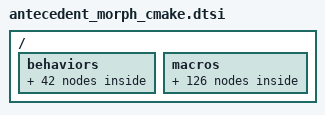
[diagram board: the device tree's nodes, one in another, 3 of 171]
// CMake schema version v0.8
// Automatically generated by Antecedent Morph Configurator

/ {
    behaviors {
        // Mod-Morphs
        // Base layer
        // NE
        amcmkneagm: amcmkneagm {
            compatible = "zmk,behavior-mod-morph";
            #binding-cells = <0>;
            bindings = <&amcmknea>, <&amcmkneg>;
            mods = <(MOD_LGUI)>;
        };
        amcmknecagm: amcmknecagm {
            compatible = "zmk,behavior-mod-morph";
            #binding-cells = <0>;
            bindings = <&amcmknec>, <&amcmkneagm>;
            mods = <(MOD_LALT|MOD_LGUI)>;
        };
        amcmknem: amcmknem {
            compatible = "zmk,behavior-mod-morph";
            #binding-cells = <0>;
            bindings = <&amcmkne>, <&amcmknecagm>;
            mods = <(MOD_LCTL|MOD_LALT|MOD_LGUI)>;
        };
        // E
        amcmkeagm: amcmkeagm {
            compatible = "zmk,behavior-mod-morph";
            #binding-cells = <0>;
            bindings = <&amcmkea>, <&amcmkeg>;
            mods = <(MOD_LGUI)>;
        };
        amcmkecagm: amcmkecagm {
            compatible = "zmk,behavior-mod-morph";
            #binding-cells = <0>;
            bindings = <&amcmkec>, <&amcmkeagm>;
            mods = <(MOD_LALT|MOD_LGUI)>;
        };
        amcmkem: amcmkem {
            compatible = "zmk,behavior-mod-morph";
            #binding-cells = <0>;
            bindings = <&amcmke>, <&amcmkecagm>;
            mods = <(MOD_LCTL|MOD_LALT|MOD_LGUI)>;
        };
        // SE
        amcmkseagm: amcmkseagm {
            compatible = "zmk,behavior-mod-morph";
            #binding-cells = <0>;
            bindings = <&amcmksea>, <&amcmkseg>;
            mods = <(MOD_LGUI)>;
        };
        amcmksecagm: amcmksecagm {
            compatible = "zmk,behavior-mod-morph";
            #binding-cells = <0>;
            bindings = <&amcmksec>, <&amcmkseagm>;
            mods = <(MOD_LALT|MOD_LGUI)>;
        };
        amcmksem: amcmksem {
            compatible = "zmk,behavior-mod-morph";
            #binding-cells = <0>;
            bindings = <&amcmkse>, <&amcmksecagm>;
            mods = <(MOD_LCTL|MOD_LALT|MOD_LGUI)>;
        };
        // NW
        amcmknwagm: amcmknwagm {
            compatible = "zmk,behavior-mod-morph";
            #binding-cells = <0>;
            bindings = <&amcmknwa>, <&amcmknwg>;
            mods = <(MOD_RGUI)>;
        };
        amcmknwcagm: amcmknwcagm {
            compatible = "zmk,behavior-mod-morph";
            #binding-cells = <0>;
            bindings = <&amcmknwc>, <&amcmknwagm>;
            mods = <(MOD_RALT|MOD_RGUI)>;
        };
        amcmknwm: amcmknwm {
            compatible = "zmk,behavior-mod-morph";
            #binding-cells = <0>;
            bindings = <&amcmknw>, <&amcmknwcagm>;
            mods = <(MOD_RCTL|MOD_RALT|MOD_RGUI)>;
        };
        // W
        amcmkwagm: amcmkwagm {
            compatible = "zmk,behavior-mod-morph";
            #binding-cells = <0>;
            bindings = <&amcmkwa>, <&amcmkwg>;
            mods = <(MOD_RGUI)>;
        };
        amcmkwcagm: amcmkwcagm {
            compatible = "zmk,behavior-mod-morph";
            #binding-cells = <0>;
            bindings = <&amcmkwc>, <&amcmkwagm>;
            mods = <(MOD_RALT|MOD_RGUI)>;
        };
        amcmkwm: amcmkwm {
            compatible = "zmk,behavior-mod-morph";
            #binding-cells = <0>;
            bindings = <&amcmkw>, <&amcmkwcagm>;
            mods = <(MOD_RCTL|MOD_RALT|MOD_RGUI)>;
        };
        // SW
        amcmkswagm: amcmkswagm {
            compatible = "zmk,behavior-mod-morph";
            #binding-cells = <0>;
            bindings = <&amcmkswa>, <&amcmkswg>;
            mods = <(MOD_RGUI)>;
        };
        amcmkswcagm: amcmkswcagm {
            compatible = "zmk,behavior-mod-morph";
            #binding-cells = <0>;
            bindings = <&amcmkswc>, <&amcmkswagm>;
            mods = <(MOD_RALT|MOD_RGUI)>;
        };
        amcmkswm: amcmkswm {
            compatible = "zmk,behavior-mod-morph";
            #binding-cells = <0>;
            bindings = <&amcmksw>, <&amcmkswcagm>;
            mods = <(MOD_RCTL|MOD_RALT|MOD_RGUI)>;
        };
        // Antecedent Morphs
        amcmkne: am_cmk_ne {
            compatible = "zmk,behavior-antecedent-morph";
            label = "AM_CMK_NE";
            #binding-cells = <0>;
            defaults = <&none>;
            bindings = <&amcmk_addexecutable>, <&amcmk_break>, <&amcmk_cmake>, <&amcmk_findprogram>, <&amcmk_generateexporth>, <&amcmk_object>, <&amcmk_public>, <&amcmk_required>, <&amcmk_static>, <&amcmk_targetsources>, <&amcmk_while>, <&amcmk_m>, <&amcmk_bool1>, <&kp DQT>, <&kp LT>, <&amcmk_standard>, <&amcmk_m2>;
            antecedents = <A B C F G O P R S T W SQT FSLH RBRC DLLR UNDER LBKT>;
            max-delay-ms = <U_ANTMORPH_DELAY>;
        };
        amcmknec: am_cmk_ne_c {
            compatible = "zmk,behavior-antecedent-morph";
            label = "AM_CMK_NE_C";
            #binding-cells = <0>;
            defaults = <&none>;
            bindings = <&amcmk_shared>, <&amcmk_endwhile>, <&amcmk_m1>, <&amcmk_standardrequire>;
            antecedents = <S W DLLR UNDER>;
            max-delay-ms = <U_ANTMORPH_DELAY>;
        };
        amcmknea: am_cmk_ne_a {
            compatible = "zmk,behavior-antecedent-morph";
            label = "AM_CMK_NE_A";
            #binding-cells = <0>;
            defaults = <&none>;
            bindings = <&amcmk_standardextensi>;
            antecedents = <UNDER>;
            max-delay-ms = <U_ANTMORPH_DELAY>;
        };
        amcmkneg: am_cmk_ne_g {
            compatible = "zmk,behavior-antecedent-morph";
            label = "AM_CMK_NE_G";
            #binding-cells = <0>;
            defaults = <&none>;
            bindings = <&none>;
            antecedents = <0x070100>;
            max-delay-ms = <U_ANTMORPH_DELAY>;
        };
        amcmke: am_cmk_e {
            compatible = "zmk,behavior-antecedent-morph";
            label = "AM_CMK_E";
            #binding-cells = <0>;
            defaults = <&none>;
            bindings = <&amcmk_addlibrary>, <&amcmk_bool>, <&amcmk_configurefile>, <&amcmk_executeprocess>, <&amcmk_findpackage>, <&amcmk_getcmakepropert>, <&amcmk_install>, <&amcmk_languages>, <&amcmk_project>, <&amcmk_return>, <&amcmk_set>, <&amcmk_targetlinklibra>, <&amcmk_version>, <&amcmk_01>, <&amcmk_10>, <&amcmk_330>, <&amcmk_cmake1>, <&amcmk_if1>, <&kp RPAR>, <&kp LBRC>, <&amcmk_not>, <&amcmk_only>, <&amcmk_or>, <&amcmk_and>, <&amcmk_currentsourcedi>, <&amcmk_m3>, <&amcmk_m6>, <&amcmk_cmake_v08>;
            antecedents = <A B C E F G I L P R S T V N0 N1 N3 DOT FSLH RBRC DLLR EXCL AT PIPE AMPS UNDER LBKT RBKT SPACE>;
            max-delay-ms = <U_ANTMORPH_DELAY>;
        };
        amcmkec: am_cmk_e_c {
            compatible = "zmk,behavior-antecedent-morph";
            label = "AM_CMK_E_C";
            #binding-cells = <0>;
            defaults = <&none>;
            bindings = <&amcmk_addlinkoptions>, <&amcmk_command>, <&amcmk_findlibrary>, <&amcmk_targetlinkoptio>, <&amcmk_cmake2>, <&amcmk_currentbinarydi>, <&amcmk_m4>, <&amcmk_m7>;
            antecedents = <A C F T DLLR UNDER LBKT RBKT>;
            max-delay-ms = <U_ANTMORPH_DELAY>;
        };
        amcmkea: am_cmk_e_a {
            compatible = "zmk,behavior-antecedent-morph";
            label = "AM_CMK_E_A";
            #binding-cells = <0>;
            defaults = <&none>;
            bindings = <&amcmk_currentlistdir>, <&amcmk_m5>, <&amcmk_m8>;
            antecedents = <UNDER LBKT RBKT>;
            max-delay-ms = <U_ANTMORPH_DELAY>;
        };
        amcmkeg: am_cmk_e_g {
            compatible = "zmk,behavior-antecedent-morph";
            label = "AM_CMK_E_G";
            #binding-cells = <0>;
            defaults = <&none>;
            bindings = <&amcmk_currentlistfile>;
            antecedents = <UNDER>;
            max-delay-ms = <U_ANTMORPH_DELAY>;
        };
        amcmkse: am_cmk_se {
            compatible = "zmk,behavior-antecedent-morph";
            label = "AM_CMK_SE";
            #binding-cells = <0>;
            defaults = <&none>;
            bindings = <&amcmk_addtestname>, <&amcmk_cmakeminimumreq>, <&amcmk_enabletesting>, <&amcmk_foreach>, <&amcmk_getproperty>, <&amcmk_private>, <&amcmk_setproperty>, <&amcmk_targetlinkdirec>, <&amcmk_regularexpressi>;
            antecedents = <A C E F G P S T UNDER>;
            max-delay-ms = <U_ANTMORPH_DELAY>;
        };
        amcmksec: am_cmk_se_c {
            compatible = "zmk,behavior-antecedent-morph";
            label = "AM_CMK_SE_C";
            #binding-cells = <0>;
            defaults = <&none>;
            bindings = <&amcmk_cmakepolicy>, <&amcmk_endforeach>, <&amcmk_settestspropert>, <&amcmk_istoplevel>;
            antecedents = <C F S UNDER>;
            max-delay-ms = <U_ANTMORPH_DELAY>;
        };
        amcmksea: am_cmk_se_a {
            compatible = "zmk,behavior-antecedent-morph";
            label = "AM_CMK_SE_A";
            #binding-cells = <0>;
            defaults = <&none>;
            bindings = <&none>;
            antecedents = <0x070100>;
            max-delay-ms = <U_ANTMORPH_DELAY>;
        };
        amcmkseg: am_cmk_se_g {
            compatible = "zmk,behavior-antecedent-morph";
            label = "AM_CMK_SE_G";
            #binding-cells = <0>;
            defaults = <&none>;
            bindings = <&none>;
            antecedents = <0x070100>;
            max-delay-ms = <U_ANTMORPH_DELAY>;
        };
        amcmknw: am_cmk_nw {
            compatible = "zmk,behavior-antecedent-morph";
            label = "AM_CMK_NW";
            #binding-cells = <0>;
            defaults = <&none>;
            bindings = <&amcmk_addsubdirectory>, <&amcmk_block>, <&amcmk_cmakepath>, <&amcmk_elseif>, <&amcmk_file>, <&amcmk_getfilenamecomp>, <&amcmk_include>, <&amcmk_module>, <&amcmk_project1>, <&amcmk_string>, <&amcmk_targetincludedi>, <&amcmk_install1>;
            antecedents = <A B C E F G I M P S T UNDER>;
            max-delay-ms = <U_ANTMORPH_DELAY>;
        };
        amcmknwc: am_cmk_nw_c {
            compatible = "zmk,behavior-antecedent-morph";
            label = "AM_CMK_NW_C";
            #binding-cells = <0>;
            defaults = <&none>;
            bindings = <&amcmk_adddependencies>, <&amcmk_endblock>, <&amcmk_findfile>, <&amcmk_targetprecompil>;
            antecedents = <A B F T>;
            max-delay-ms = <U_ANTMORPH_DELAY>;
        };
        amcmknwa: am_cmk_nw_a {
            compatible = "zmk,behavior-antecedent-morph";
            label = "AM_CMK_NW_A";
            #binding-cells = <0>;
            defaults = <&none>;
            bindings = <&amcmk_findpath>;
            antecedents = <F>;
            max-delay-ms = <U_ANTMORPH_DELAY>;
        };
        amcmknwg: am_cmk_nw_g {
            compatible = "zmk,behavior-antecedent-morph";
            label = "AM_CMK_NW_G";
            #binding-cells = <0>;
            defaults = <&none>;
            bindings = <&none>;
            antecedents = <0x070100>;
            max-delay-ms = <U_ANTMORPH_DELAY>;
        };
        amcmkw: am_cmk_w {
            compatible = "zmk,behavior-antecedent-morph";
            label = "AM_CMK_W";
            #binding-cells = <0>;
            defaults = <&none>;
            bindings = <&amcmk_addcompiledefin>, <&amcmk_continue>, <&amcmk_else>, <&amcmk_gettargetproper>, <&amcmk_headers>, <&amcmk_if>, <&amcmk_list>, <&amcmk_matches>, <&amcmk_false>, <&amcmk_option>, <&amcmk_properties>, <&amcmk_settargetproper>, <&amcmk_targetcompilede>, <&amcmk_true>, <&amcmk_cmakecommand>, <&amcmk_std>;
            antecedents = <A C E G H I L M N O P S T Y DLLR UNDER>;
            max-delay-ms = <U_ANTMORPH_DELAY>;
        };
        amcmkwc: am_cmk_w_c {
            compatible = "zmk,behavior-antecedent-morph";
            label = "AM_CMK_W_C";
            #binding-cells = <0>;
            defaults = <&none>;
            bindings = <&amcmk_addcompileoptio>, <&amcmk_getdirectorypro>, <&amcmk_endif>, <&amcmk_optionenable>, <&amcmk_setdirectorypro>, <&amcmk_targetcompileop>;
            antecedents = <A G I O S T>;
            max-delay-ms = <U_ANTMORPH_DELAY>;
        };
        amcmkwa: am_cmk_w_a {
            compatible = "zmk,behavior-antecedent-morph";
            label = "AM_CMK_W_A";
            #binding-cells = <0>;
            defaults = <&none>;
            bindings = <&amcmk_ifnot>, <&amcmk_targetcompilefe>;
            antecedents = <I T>;
            max-delay-ms = <U_ANTMORPH_DELAY>;
        };
        amcmkwg: am_cmk_w_g {
            compatible = "zmk,behavior-antecedent-morph";
            label = "AM_CMK_W_G";
            #binding-cells = <0>;
            defaults = <&none>;
            bindings = <&none>;
            antecedents = <0x070100>;
            max-delay-ms = <U_ANTMORPH_DELAY>;
        };
        amcmksw: am_cmk_sw {
            compatible = "zmk,behavior-antecedent-morph";
            label = "AM_CMK_SW";
            #binding-cells = <0>;
            defaults = <&none>;
            bindings = <&amcmk_addcustomtarget>, <&amcmk_cmakelanguage>, <&amcmk_fixturesrequire>, <&amcmk_getsourcefilepr>, <&amcmk_interface>, <&amcmk_message>, <&amcmk_resourcegroups>;
            antecedents = <A C F G I M R>;
            max-delay-ms = <U_ANTMORPH_DELAY>;
        };
        amcmkswc: am_cmk_sw_c {
            compatible = "zmk,behavior-antecedent-morph";
            label = "AM_CMK_SW_C";
            #binding-cells = <0>;
            defaults = <&none>;
            bindings = <&amcmk_addcustomcomman>, <&amcmk_fixturessetup>, <&amcmk_gettestproperty>, <&amcmk_imported>, <&amcmk_resourcelock>, <&amcmk_setsourcefilesp>;
            antecedents = <A F G I R S>;
            max-delay-ms = <U_ANTMORPH_DELAY>;
        };
        amcmkswa: am_cmk_sw_a {
            compatible = "zmk,behavior-antecedent-morph";
            label = "AM_CMK_SW_A";
            #binding-cells = <0>;
            defaults = <&none>;
            bindings = <&amcmk_fixturescleanup>;
            antecedents = <F>;
            max-delay-ms = <U_ANTMORPH_DELAY>;
        };
        amcmkswg: am_cmk_sw_g {
            compatible = "zmk,behavior-antecedent-morph";
            label = "AM_CMK_SW_G";
            #binding-cells = <0>;
            defaults = <&none>;
            bindings = <&none>;
            antecedents = <0x070100>;
            max-delay-ms = <U_ANTMORPH_DELAY>;
        };
    };
    macros {
        // 'A'
        amcmk_addexecutable: amcmk_addexecutable {
            compatible = "zmk,behavior-macro";
            #binding-cells = <0>;
            wait-ms = <U_ANTMORPH_MACRO_WAIT>;
            tap-ms = <U_ANTMORPH_MACRO_TAP>;
            // (a)dd_executable(
            bindings = <&macro_tap &kp D &kp D &kp UNDER &kp E &kp X &kp E &kp C &kp U &kp T &kp A &kp B &kp L &kp E &kp LPAR>;
        };
        amcmk_addlibrary: amcmk_addlibrary {
            compatible = "zmk,behavior-macro";
            #binding-cells = <0>;
            wait-ms = <U_ANTMORPH_MACRO_WAIT>;
            tap-ms = <U_ANTMORPH_MACRO_TAP>;
            // (a)dd_library(
            bindings = <&macro_tap &kp D &kp D &kp UNDER &kp L &kp I &kp B &kp R &kp A &kp R &kp Y &kp LPAR>;
        };
        amcmk_addlinkoptions: amcmk_addlinkoptions {
            compatible = "zmk,behavior-macro";
            #binding-cells = <0>;
            wait-ms = <U_ANTMORPH_MACRO_WAIT>;
            tap-ms = <U_ANTMORPH_MACRO_TAP>;
            // (a)dd_link_options(
            bindings = <&macro_release &kp LCTRL>, <&macro_tap &kp D &kp D &kp UNDER &kp L &kp I &kp N &kp K &kp UNDER &kp O &kp P &kp T &kp I &kp O &kp N &kp S &kp LPAR>;
        };
        amcmk_addtestname: amcmk_addtestname {
            compatible = "zmk,behavior-macro";
            #binding-cells = <0>;
            wait-ms = <U_ANTMORPH_MACRO_WAIT>;
            tap-ms = <U_ANTMORPH_MACRO_TAP>;
            // (a)dd_test(NAME 
            bindings = <&macro_tap &kp D &kp D &kp UNDER &kp T &kp E &kp S &kp T &kp LPAR &kp LS(N) &kp LS(A) &kp LS(M) &kp LS(E) &kp SPACE>;
        };
        amcmk_addsubdirectory: amcmk_addsubdirectory {
            compatible = "zmk,behavior-macro";
            #binding-cells = <0>;
            wait-ms = <U_ANTMORPH_MACRO_WAIT>;
            tap-ms = <U_ANTMORPH_MACRO_TAP>;
            // (a)dd_subdirectory(
            bindings = <&macro_tap &kp D &kp D &kp UNDER &kp S &kp U &kp B &kp D &kp I &kp R &kp E &kp C &kp T &kp O &kp R &kp Y &kp LPAR>;
        };
        amcmk_adddependencies: amcmk_adddependencies {
            compatible = "zmk,behavior-macro";
            #binding-cells = <0>;
            wait-ms = <U_ANTMORPH_MACRO_WAIT>;
            tap-ms = <U_ANTMORPH_MACRO_TAP>;
            // (a)dd_dependencies(
            bindings = <&macro_release &kp RCTRL>, <&macro_tap &kp D &kp D &kp UNDER &kp D &kp E &kp P &kp E &kp N &kp D &kp E &kp N &kp C &kp I &kp E &kp S &kp LPAR>;
        };
        amcmk_addcompiledefin: amcmk_addcompiledefin {
            compatible = "zmk,behavior-macro";
            #binding-cells = <0>;
            wait-ms = <U_ANTMORPH_MACRO_WAIT>;
            tap-ms = <U_ANTMORPH_MACRO_TAP>;
            // (a)dd_compile_definitions(
            bindings = <&macro_tap &kp D &kp D &kp UNDER &kp C &kp O &kp M &kp P &kp I &kp L &kp E &kp UNDER &kp D &kp E &kp F &kp I &kp N &kp I &kp T &kp I &kp O &kp N &kp S &kp LPAR>;
        };
        amcmk_addcompileoptio: amcmk_addcompileoptio {
            compatible = "zmk,behavior-macro";
            #binding-cells = <0>;
            wait-ms = <U_ANTMORPH_MACRO_WAIT>;
            tap-ms = <U_ANTMORPH_MACRO_TAP>;
            // (a)dd_compile_options(
            bindings = <&macro_release &kp RCTRL>, <&macro_tap &kp D &kp D &kp UNDER &kp C &kp O &kp M &kp P &kp I &kp L &kp E &kp UNDER &kp O &kp P &kp T &kp I &kp O &kp N &kp S &kp LPAR>;
        };
        amcmk_addcustomtarget: amcmk_addcustomtarget {
            compatible = "zmk,behavior-macro";
            #binding-cells = <0>;
            wait-ms = <U_ANTMORPH_MACRO_WAIT>;
            tap-ms = <U_ANTMORPH_MACRO_TAP>;
            // (a)dd_custom_target(
            bindings = <&macro_tap &kp D &kp D &kp UNDER &kp C &kp U &kp S &kp T &kp O &kp M &kp UNDER &kp T &kp A &kp R &kp G &kp E &kp T &kp LPAR>;
        };
        amcmk_addcustomcomman: amcmk_addcustomcomman {
            compatible = "zmk,behavior-macro";
            #binding-cells = <0>;
            wait-ms = <U_ANTMORPH_MACRO_WAIT>;
            tap-ms = <U_ANTMORPH_MACRO_TAP>;
            // (a)dd_custom_command(
            bindings = <&macro_release &kp RCTRL>, <&macro_tap &kp D &kp D &kp UNDER &kp C &kp U &kp S &kp T &kp O &kp M &kp UNDER &kp C &kp O &kp M &kp M &kp A &kp N &kp D &kp LPAR>;
        };
        // 'B'
        amcmk_break: amcmk_break {
            compatible = "zmk,behavior-macro";
            #binding-cells = <0>;
            wait-ms = <U_ANTMORPH_MACRO_WAIT>;
            tap-ms = <U_ANTMORPH_MACRO_TAP>;
            // (b)reak()
            bindings = <&macro_tap &kp R &kp E &kp A &kp K &kp LPAR &kp RPAR>;
        };
        amcmk_bool: amcmk_bool {
            compatible = "zmk,behavior-macro";
            #binding-cells = <0>;
            wait-ms = <U_ANTMORPH_MACRO_WAIT>;
            tap-ms = <U_ANTMORPH_MACRO_TAP>;
            // [b]$<BOOL:
            bindings = <&macro_tap &kp BSPC &kp DLLR &kp LT &kp LS(B) &kp LS(O) &kp LS(O) &kp LS(L) &kp COLON>;
        };
        amcmk_block: amcmk_block {
            compatible = "zmk,behavior-macro";
            #binding-cells = <0>;
            wait-ms = <U_ANTMORPH_MACRO_WAIT>;
            tap-ms = <U_ANTMORPH_MACRO_TAP>;
            // (b)lock()
            bindings = <&macro_tap &kp L &kp O &kp C &kp K &kp LPAR &kp RPAR>;
        };
        amcmk_endblock: amcmk_endblock {
            compatible = "zmk,behavior-macro";
            #binding-cells = <0>;
            wait-ms = <U_ANTMORPH_MACRO_WAIT>;
            tap-ms = <U_ANTMORPH_MACRO_TAP>;
            // [b]endblock()
            bindings = <&macro_release &kp RCTRL>, <&macro_tap &kp BSPC &kp E &kp N &kp D &kp B &kp L &kp O &kp C &kp K &kp LPAR &kp RPAR>;
        };
        // 'C'
        amcmk_cmake: amcmk_cmake {
            compatible = "zmk,behavior-macro";
            #binding-cells = <0>;
            wait-ms = <U_ANTMORPH_MACRO_WAIT>;
            tap-ms = <U_ANTMORPH_MACRO_TAP>;
            // [c]CMAKE_
            bindings = <&macro_tap &kp BSPC &kp LS(C) &kp LS(M) &kp LS(A) &kp LS(K) &kp LS(E) &kp UNDER>;
        };
        amcmk_configurefile: amcmk_configurefile {
            compatible = "zmk,behavior-macro";
            #binding-cells = <0>;
            wait-ms = <U_ANTMORPH_MACRO_WAIT>;
            tap-ms = <U_ANTMORPH_MACRO_TAP>;
            // (c)onfigure_file(
            bindings = <&macro_tap &kp O &kp N &kp F &kp I &kp G &kp U &kp R &kp E &kp UNDER &kp F &kp I &kp L &kp E &kp LPAR>;
        };
        amcmk_command: amcmk_command {
            compatible = "zmk,behavior-macro";
            #binding-cells = <0>;
            wait-ms = <U_ANTMORPH_MACRO_WAIT>;
            tap-ms = <U_ANTMORPH_MACRO_TAP>;
            // [c]COMMAND
            bindings = <&macro_release &kp LCTRL>, <&macro_tap &kp BSPC &kp LS(C) &kp LS(O) &kp LS(M) &kp LS(M) &kp LS(A) &kp LS(N) &kp LS(D)>;
        };
        amcmk_cmakeminimumreq: amcmk_cmakeminimumreq {
            compatible = "zmk,behavior-macro";
            #binding-cells = <0>;
            wait-ms = <U_ANTMORPH_MACRO_WAIT>;
            tap-ms = <U_ANTMORPH_MACRO_TAP>;
            // (c)make_minimum_required(VERSION 
            bindings = <&macro_tap &kp M &kp A &kp K &kp E &kp UNDER &kp M &kp I &kp N &kp I &kp M &kp U &kp M &kp UNDER &kp R &kp E &kp Q &kp U &kp I &kp R &kp E &kp D &kp LPAR &kp LS(V) &kp LS(E) &kp LS(R) &kp LS(S) &kp LS(I) &kp LS(O) &kp LS(N) &kp SPACE>;
        };
        amcmk_cmakepolicy: amcmk_cmakepolicy {
            compatible = "zmk,behavior-macro";
            #binding-cells = <0>;
            wait-ms = <U_ANTMORPH_MACRO_WAIT>;
            tap-ms = <U_ANTMORPH_MACRO_TAP>;
            // (c)make_policy(
            bindings = <&macro_release &kp LCTRL>, <&macro_tap &kp M &kp A &kp K &kp E &kp UNDER &kp P &kp O &kp L &kp I &kp C &kp Y &kp LPAR>;
        };
        amcmk_cmakepath: amcmk_cmakepath {
            compatible = "zmk,behavior-macro";
            #binding-cells = <0>;
            wait-ms = <U_ANTMORPH_MACRO_WAIT>;
            tap-ms = <U_ANTMORPH_MACRO_TAP>;
            // (c)make_path(
            bindings = <&macro_tap &kp M &kp A &kp K &kp E &kp UNDER &kp P &kp A &kp T &kp H &kp LPAR>;
        };
        amcmk_continue: amcmk_continue {
            compatible = "zmk,behavior-macro";
            #binding-cells = <0>;
            wait-ms = <U_ANTMORPH_MACRO_WAIT>;
            tap-ms = <U_ANTMORPH_MACRO_TAP>;
            // (c)ontinue()
            bindings = <&macro_tap &kp O &kp N &kp T &kp I &kp N &kp U &kp E &kp LPAR &kp RPAR>;
        };
        amcmk_cmakelanguage: amcmk_cmakelanguage {
            compatible = "zmk,behavior-macro";
            #binding-cells = <0>;
            wait-ms = <U_ANTMORPH_MACRO_WAIT>;
            tap-ms = <U_ANTMORPH_MACRO_TAP>;
            // (c)make_language(
            bindings = <&macro_tap &kp M &kp A &kp K &kp E &kp UNDER &kp L &kp A &kp N &kp G &kp U &kp A &kp G &kp E &kp LPAR>;
        };
        // 'E'
        amcmk_executeprocess: amcmk_executeprocess {
            compatible = "zmk,behavior-macro";
            #binding-cells = <0>;
            wait-ms = <U_ANTMORPH_MACRO_WAIT>;
            tap-ms = <U_ANTMORPH_MACRO_TAP>;
            // (e)xecute_process(
            bindings = <&macro_tap &kp X &kp E &kp C &kp U &kp T &kp E &kp UNDER &kp P &kp R &kp O &kp C &kp E &kp S &kp S &kp LPAR>;
        };
        amcmk_enabletesting: amcmk_enabletesting {
            compatible = "zmk,behavior-macro";
            #binding-cells = <0>;
            wait-ms = <U_ANTMORPH_MACRO_WAIT>;
            tap-ms = <U_ANTMORPH_MACRO_TAP>;
            // (e)nable_testing()
            bindings = <&macro_tap &kp N &kp A &kp B &kp L &kp E &kp UNDER &kp T &kp E &kp S &kp T &kp I &kp N &kp G &kp LPAR &kp RPAR>;
        };
        amcmk_elseif: amcmk_elseif {
            compatible = "zmk,behavior-macro";
            #binding-cells = <0>;
            wait-ms = <U_ANTMORPH_MACRO_WAIT>;
            tap-ms = <U_ANTMORPH_MACRO_TAP>;
            // (e)lseif(
            bindings = <&macro_tap &kp L &kp S &kp E &kp I &kp F &kp LPAR>;
        };
        amcmk_else: amcmk_else {
            compatible = "zmk,behavior-macro";
            #binding-cells = <0>;
            wait-ms = <U_ANTMORPH_MACRO_WAIT>;
            tap-ms = <U_ANTMORPH_MACRO_TAP>;
            // (e)lse()
            bindings = <&macro_tap &kp L &kp S &kp E &kp LPAR &kp RPAR>;
        };
        // 'F'
        amcmk_findprogram: amcmk_findprogram {
            compatible = "zmk,behavior-macro";
            #binding-cells = <0>;
            wait-ms = <U_ANTMORPH_MACRO_WAIT>;
            tap-ms = <U_ANTMORPH_MACRO_TAP>;
            // (f)ind_program(
            bindings = <&macro_tap &kp I &kp N &kp D &kp UNDER &kp P &kp R &kp O &kp G &kp R &kp A &kp M &kp LPAR>;
        };
        amcmk_findpackage: amcmk_findpackage {
            compatible = "zmk,behavior-macro";
            #binding-cells = <0>;
            wait-ms = <U_ANTMORPH_MACRO_WAIT>;
            tap-ms = <U_ANTMORPH_MACRO_TAP>;
            // (f)ind_package(
            bindings = <&macro_tap &kp I &kp N &kp D &kp UNDER &kp P &kp A &kp C &kp K &kp A &kp G &kp E &kp LPAR>;
        };
        amcmk_findlibrary: amcmk_findlibrary {
            compatible = "zmk,behavior-macro";
            #binding-cells = <0>;
            wait-ms = <U_ANTMORPH_MACRO_WAIT>;
            tap-ms = <U_ANTMORPH_MACRO_TAP>;
            // (f)ind_library(
            bindings = <&macro_release &kp LCTRL>, <&macro_tap &kp I &kp N &kp D &kp UNDER &kp L &kp I &kp B &kp R &kp A &kp R &kp Y &kp LPAR>;
        };
        amcmk_foreach: amcmk_foreach {
            compatible = "zmk,behavior-macro";
            #binding-cells = <0>;
            wait-ms = <U_ANTMORPH_MACRO_WAIT>;
            tap-ms = <U_ANTMORPH_MACRO_TAP>;
            // (f)oreach(
            bindings = <&macro_tap &kp O &kp R &kp E &kp A &kp C &kp H &kp LPAR>;
        };
        amcmk_endforeach: amcmk_endforeach {
            compatible = "zmk,behavior-macro";
            #binding-cells = <0>;
            wait-ms = <U_ANTMORPH_MACRO_WAIT>;
            tap-ms = <U_ANTMORPH_MACRO_TAP>;
            // [f]endforeach()
            bindings = <&macro_release &kp LCTRL>, <&macro_tap &kp BSPC &kp E &kp N &kp D &kp F &kp O &kp R &kp E &kp A &kp C &kp H &kp LPAR &kp RPAR>;
        };
        amcmk_file: amcmk_file {
            compatible = "zmk,behavior-macro";
            #binding-cells = <0>;
            wait-ms = <U_ANTMORPH_MACRO_WAIT>;
            tap-ms = <U_ANTMORPH_MACRO_TAP>;
            // (f)ile(
            bindings = <&macro_tap &kp I &kp L &kp E &kp LPAR>;
        };
        amcmk_findfile: amcmk_findfile {
            compatible = "zmk,behavior-macro";
            #binding-cells = <0>;
            wait-ms = <U_ANTMORPH_MACRO_WAIT>;
            tap-ms = <U_ANTMORPH_MACRO_TAP>;
            // (f)ind_file(
            bindings = <&macro_release &kp RCTRL>, <&macro_tap &kp I &kp N &kp D &kp UNDER &kp F &kp I &kp L &kp E &kp LPAR>;
        };
        amcmk_findpath: amcmk_findpath {
            compatible = "zmk,behavior-macro";
            #binding-cells = <0>;
            wait-ms = <U_ANTMORPH_MACRO_WAIT>;
            tap-ms = <U_ANTMORPH_MACRO_TAP>;
            // (f)ind_path(
            bindings = <&macro_release &kp RALT>, <&macro_tap &kp RALT>, <&macro_tap &kp I &kp N &kp D &kp UNDER &kp P &kp A &kp T &kp H &kp LPAR>;
        };
        amcmk_fixturesrequire: amcmk_fixturesrequire {
            compatible = "zmk,behavior-macro";
            #binding-cells = <0>;
            wait-ms = <U_ANTMORPH_MACRO_WAIT>;
            tap-ms = <U_ANTMORPH_MACRO_TAP>;
            // [f]FIXTURES_REQUIRED
            bindings = <&macro_tap &kp BSPC &kp LS(F) &kp LS(I) &kp LS(X) &kp LS(T) &kp LS(U) &kp LS(R) &kp LS(E) &kp LS(S) &kp UNDER &kp LS(R) &kp LS(E) &kp LS(Q) &kp LS(U) &kp LS(I) &kp LS(R) &kp LS(E) &kp LS(D)>;
        };
        amcmk_fixturessetup: amcmk_fixturessetup {
            compatible = "zmk,behavior-macro";
            #binding-cells = <0>;
            wait-ms = <U_ANTMORPH_MACRO_WAIT>;
            tap-ms = <U_ANTMORPH_MACRO_TAP>;
            // [f]FIXTURES_SETUP
            bindings = <&macro_release &kp RCTRL>, <&macro_tap &kp BSPC &kp LS(F) &kp LS(I) &kp LS(X) &kp LS(T) &kp LS(U) &kp LS(R) &kp LS(E) &kp LS(S) &kp UNDER &kp LS(S) &kp LS(E) &kp LS(T) &kp LS(U) &kp LS(P)>;
        };
        amcmk_fixturescleanup: amcmk_fixturescleanup {
            compatible = "zmk,behavior-macro";
            #binding-cells = <0>;
            wait-ms = <U_ANTMORPH_MACRO_WAIT>;
            tap-ms = <U_ANTMORPH_MACRO_TAP>;
            // [f]FIXTURES_CLEANUP
            bindings = <&macro_release &kp RALT>, <&macro_tap &kp RALT>, <&macro_tap &kp BSPC &kp LS(F) &kp LS(I) &kp LS(X) &kp LS(T) &kp LS(U) &kp LS(R) &kp LS(E) &kp LS(S) &kp UNDER &kp LS(C) &kp LS(L) &kp LS(E) &kp LS(A) &kp LS(N) &kp LS(U) &kp LS(P)>;
        };
        // 'G'
        amcmk_generateexporth: amcmk_generateexporth {
            compatible = "zmk,behavior-macro";
            #binding-cells = <0>;
            wait-ms = <U_ANTMORPH_MACRO_WAIT>;
            tap-ms = <U_ANTMORPH_MACRO_TAP>;
            // (g)enerate_export_header(
            bindings = <&macro_tap &kp E &kp N &kp E &kp R &kp A &kp T &kp E &kp UNDER &kp E &kp X &kp P &kp O &kp R &kp T &kp UNDER &kp H &kp E &kp A &kp D &kp E &kp R &kp LPAR>;
        };
        amcmk_getcmakepropert: amcmk_getcmakepropert {
            compatible = "zmk,behavior-macro";
            #binding-cells = <0>;
            wait-ms = <U_ANTMORPH_MACRO_WAIT>;
            tap-ms = <U_ANTMORPH_MACRO_TAP>;
            // (g)et_cmake_property(
            bindings = <&macro_tap &kp E &kp T &kp UNDER &kp C &kp M &kp A &kp K &kp E &kp UNDER &kp P &kp R &kp O &kp P &kp E &kp R &kp T &kp Y &kp LPAR>;
        };
        amcmk_getproperty: amcmk_getproperty {
            compatible = "zmk,behavior-macro";
            #binding-cells = <0>;
            wait-ms = <U_ANTMORPH_MACRO_WAIT>;
            tap-ms = <U_ANTMORPH_MACRO_TAP>;
            // (g)et_property(
            bindings = <&macro_tap &kp E &kp T &kp UNDER &kp P &kp R &kp O &kp P &kp E &kp R &kp T &kp Y &kp LPAR>;
        };
        amcmk_getfilenamecomp: amcmk_getfilenamecomp {
            compatible = "zmk,behavior-macro";
            #binding-cells = <0>;
            wait-ms = <U_ANTMORPH_MACRO_WAIT>;
            tap-ms = <U_ANTMORPH_MACRO_TAP>;
            // (g)et_filename_component(
            bindings = <&macro_tap &kp E &kp T &kp UNDER &kp F &kp I &kp L &kp E &kp N &kp A &kp M &kp E &kp UNDER &kp C &kp O &kp M &kp P &kp O &kp N &kp E &kp N &kp T &kp LPAR>;
        };
        amcmk_gettargetproper: amcmk_gettargetproper {
            compatible = "zmk,behavior-macro";
            #binding-cells = <0>;
            wait-ms = <U_ANTMORPH_MACRO_WAIT>;
            tap-ms = <U_ANTMORPH_MACRO_TAP>;
            // (g)et_target_property(
            bindings = <&macro_tap &kp E &kp T &kp UNDER &kp T &kp A &kp R &kp G &kp E &kp T &kp UNDER &kp P &kp R &kp O &kp P &kp E &kp R &kp T &kp Y &kp LPAR>;
        };
        amcmk_getdirectorypro: amcmk_getdirectorypro {
            compatible = "zmk,behavior-macro";
            #binding-cells = <0>;
            wait-ms = <U_ANTMORPH_MACRO_WAIT>;
            tap-ms = <U_ANTMORPH_MACRO_TAP>;
            // (g)et_directory_property(
            bindings = <&macro_release &kp RCTRL>, <&macro_tap &kp E &kp T &kp UNDER &kp D &kp I &kp R &kp E &kp C &kp T &kp O &kp R &kp Y &kp UNDER &kp P &kp R &kp O &kp P &kp E &kp R &kp T &kp Y &kp LPAR>;
        };
        amcmk_getsourcefilepr: amcmk_getsourcefilepr {
            compatible = "zmk,behavior-macro";
            #binding-cells = <0>;
            wait-ms = <U_ANTMORPH_MACRO_WAIT>;
            tap-ms = <U_ANTMORPH_MACRO_TAP>;
            // (g)et_source_file_property(
            bindings = <&macro_tap &kp E &kp T &kp UNDER &kp S &kp O &kp U &kp R &kp C &kp E &kp UNDER &kp F &kp I &kp L &kp E &kp UNDER &kp P &kp R &kp O &kp P &kp E &kp R &kp T &kp Y &kp LPAR>;
        };
        amcmk_gettestproperty: amcmk_gettestproperty {
            compatible = "zmk,behavior-macro";
            #binding-cells = <0>;
            wait-ms = <U_ANTMORPH_MACRO_WAIT>;
            tap-ms = <U_ANTMORPH_MACRO_TAP>;
            // (g)et_test_property(
            bindings = <&macro_release &kp RCTRL>, <&macro_tap &kp E &kp T &kp UNDER &kp T &kp E &kp S &kp T &kp UNDER &kp P &kp R &kp O &kp P &kp E &kp R &kp T &kp Y &kp LPAR>;
        };
        // 'H'
        amcmk_headers: amcmk_headers {
            compatible = "zmk,behavior-macro";
            #binding-cells = <0>;
            wait-ms = <U_ANTMORPH_MACRO_WAIT>;
            tap-ms = <U_ANTMORPH_MACRO_TAP>;
            // [h]HEADERS
            bindings = <&macro_tap &kp BSPC &kp LS(H) &kp LS(E) &kp LS(A) &kp LS(D) &kp LS(E) &kp LS(R) &kp LS(S)>;
        };
        // 'I'
        amcmk_install: amcmk_install {
            compatible = "zmk,behavior-macro";
            #binding-cells = <0>;
            wait-ms = <U_ANTMORPH_MACRO_WAIT>;
            tap-ms = <U_ANTMORPH_MACRO_TAP>;
            // (i)nstall(
            bindings = <&macro_tap &kp N &kp S &kp T &kp A &kp L &kp L &kp LPAR>;
        };
        amcmk_include: amcmk_include {
            compatible = "zmk,behavior-macro";
            #binding-cells = <0>;
            wait-ms = <U_ANTMORPH_MACRO_WAIT>;
            tap-ms = <U_ANTMORPH_MACRO_TAP>;
            // (i)nclude(
            bindings = <&macro_tap &kp N &kp C &kp L &kp U &kp D &kp E &kp LPAR>;
        };
        amcmk_if: amcmk_if {
            compatible = "zmk,behavior-macro";
            #binding-cells = <0>;
            wait-ms = <U_ANTMORPH_MACRO_WAIT>;
            tap-ms = <U_ANTMORPH_MACRO_TAP>;
            // (i)f(
            bindings = <&macro_tap &kp F &kp LPAR>;
        };
        amcmk_endif: amcmk_endif {
            compatible = "zmk,behavior-macro";
            #binding-cells = <0>;
            wait-ms = <U_ANTMORPH_MACRO_WAIT>;
            tap-ms = <U_ANTMORPH_MACRO_TAP>;
            // [i]endif()
            bindings = <&macro_release &kp RCTRL>, <&macro_tap &kp BSPC &kp E &kp N &kp D &kp I &kp F &kp LPAR &kp RPAR>;
        };
        amcmk_ifnot: amcmk_ifnot {
            compatible = "zmk,behavior-macro";
            #binding-cells = <0>;
            wait-ms = <U_ANTMORPH_MACRO_WAIT>;
            tap-ms = <U_ANTMORPH_MACRO_TAP>;
            // (i)f(NOT 
            bindings = <&macro_release &kp RALT>, <&macro_tap &kp RALT>, <&macro_tap &kp F &kp LPAR &kp LS(N) &kp LS(O) &kp LS(T) &kp SPACE>;
        };
        amcmk_interface: amcmk_interface {
            compatible = "zmk,behavior-macro";
            #binding-cells = <0>;
            wait-ms = <U_ANTMORPH_MACRO_WAIT>;
            tap-ms = <U_ANTMORPH_MACRO_TAP>;
            // [i]INTERFACE
            bindings = <&macro_tap &kp BSPC &kp LS(I) &kp LS(N) &kp LS(T) &kp LS(E) &kp LS(R) &kp LS(F) &kp LS(A) &kp LS(C) &kp LS(E)>;
        };
        amcmk_imported: amcmk_imported {
            compatible = "zmk,behavior-macro";
            #binding-cells = <0>;
            wait-ms = <U_ANTMORPH_MACRO_WAIT>;
            tap-ms = <U_ANTMORPH_MACRO_TAP>;
            // [i]IMPORTED
            bindings = <&macro_release &kp RCTRL>, <&macro_tap &kp BSPC &kp LS(I) &kp LS(M) &kp LS(P) &kp LS(O) &kp LS(R) &kp LS(T) &kp LS(E) &kp LS(D)>;
        };
        // 'L'
        amcmk_languages: amcmk_languages {
            compatible = "zmk,behavior-macro";
            #binding-cells = <0>;
            wait-ms = <U_ANTMORPH_MACRO_WAIT>;
            tap-ms = <U_ANTMORPH_MACRO_TAP>;
            // [l]LANGUAGES
            bindings = <&macro_tap &kp BSPC &kp LS(L) &kp LS(A) &kp LS(N) &kp LS(G) &kp LS(U) &kp LS(A) &kp LS(G) &kp LS(E) &kp LS(S)>;
        };
        amcmk_list: amcmk_list {
            compatible = "zmk,behavior-macro";
            #binding-cells = <0>;
            wait-ms = <U_ANTMORPH_MACRO_WAIT>;
            tap-ms = <U_ANTMORPH_MACRO_TAP>;
            // (l)ist(
            bindings = <&macro_tap &kp I &kp S &kp T &kp LPAR>;
        };
        // 'M'
        amcmk_module: amcmk_module {
            compatible = "zmk,behavior-macro";
            #binding-cells = <0>;
            wait-ms = <U_ANTMORPH_MACRO_WAIT>;
            tap-ms = <U_ANTMORPH_MACRO_TAP>;
            // [m]MODULE
            bindings = <&macro_tap &kp BSPC &kp LS(M) &kp LS(O) &kp LS(D) &kp LS(U) &kp LS(L) &kp LS(E)>;
        };
        amcmk_matches: amcmk_matches {
            compatible = "zmk,behavior-macro";
            #binding-cells = <0>;
            wait-ms = <U_ANTMORPH_MACRO_WAIT>;
            tap-ms = <U_ANTMORPH_MACRO_TAP>;
            // [m]MATCHES
            bindings = <&macro_tap &kp BSPC &kp LS(M) &kp LS(A) &kp LS(T) &kp LS(C) &kp LS(H) &kp LS(E) &kp LS(S)>;
        };
        amcmk_message: amcmk_message {
            compatible = "zmk,behavior-macro";
            #binding-cells = <0>;
            wait-ms = <U_ANTMORPH_MACRO_WAIT>;
            tap-ms = <U_ANTMORPH_MACRO_TAP>;
            // (m)essage(
            bindings = <&macro_tap &kp E &kp S &kp S &kp A &kp G &kp E &kp LPAR>;
        };
        // 'N'
        amcmk_false: amcmk_false {
            compatible = "zmk,behavior-macro";
            #binding-cells = <0>;
            wait-ms = <U_ANTMORPH_MACRO_WAIT>;
            tap-ms = <U_ANTMORPH_MACRO_TAP>;
            // [n]FALSE
            bindings = <&macro_tap &kp BSPC &kp LS(F) &kp LS(A) &kp LS(L) &kp LS(S) &kp LS(E)>;
        };
        // 'O'
        amcmk_object: amcmk_object {
            compatible = "zmk,behavior-macro";
            #binding-cells = <0>;
            wait-ms = <U_ANTMORPH_MACRO_WAIT>;
            tap-ms = <U_ANTMORPH_MACRO_TAP>;
            // [o]OBJECT
            bindings = <&macro_tap &kp BSPC &kp LS(O) &kp LS(B) &kp LS(J) &kp LS(E) &kp LS(C) &kp LS(T)>;
        };
        amcmk_option: amcmk_option {
            compatible = "zmk,behavior-macro";
            #binding-cells = <0>;
            wait-ms = <U_ANTMORPH_MACRO_WAIT>;
            tap-ms = <U_ANTMORPH_MACRO_TAP>;
            // (o)ption(
            bindings = <&macro_tap &kp P &kp T &kp I &kp O &kp N &kp LPAR>;
        };
        amcmk_optionenable: amcmk_optionenable {
            compatible = "zmk,behavior-macro";
            #binding-cells = <0>;
            wait-ms = <U_ANTMORPH_MACRO_WAIT>;
            tap-ms = <U_ANTMORPH_MACRO_TAP>;
            // (o)ption(ENABLE_
            bindings = <&macro_release &kp RCTRL>, <&macro_tap &kp P &kp T &kp I &kp O &kp N &kp LPAR &kp LS(E) &kp LS(N) &kp LS(A) &kp LS(B) &kp LS(L) &kp LS(E) &kp UNDER>;
        };
        // 'P'
        amcmk_public: amcmk_public {
            compatible = "zmk,behavior-macro";
            #binding-cells = <0>;
            wait-ms = <U_ANTMORPH_MACRO_WAIT>;
            tap-ms = <U_ANTMORPH_MACRO_TAP>;
            // [p]PUBLIC
            bindings = <&macro_tap &kp BSPC &kp LS(P) &kp LS(U) &kp LS(B) &kp LS(L) &kp LS(I) &kp LS(C)>;
        };
        amcmk_project: amcmk_project {
            compatible = "zmk,behavior-macro";
            #binding-cells = <0>;
            wait-ms = <U_ANTMORPH_MACRO_WAIT>;
            tap-ms = <U_ANTMORPH_MACRO_TAP>;
            // (p)roject(
            bindings = <&macro_tap &kp R &kp O &kp J &kp E &kp C &kp T &kp LPAR>;
        };
        amcmk_private: amcmk_private {
            compatible = "zmk,behavior-macro";
            #binding-cells = <0>;
            wait-ms = <U_ANTMORPH_MACRO_WAIT>;
            tap-ms = <U_ANTMORPH_MACRO_TAP>;
            // [p]PRIVATE
            bindings = <&macro_tap &kp BSPC &kp LS(P) &kp LS(R) &kp LS(I) &kp LS(V) &kp LS(A) &kp LS(T) &kp LS(E)>;
        };
        amcmk_project1: amcmk_project1 {
            compatible = "zmk,behavior-macro";
            #binding-cells = <0>;
            wait-ms = <U_ANTMORPH_MACRO_WAIT>;
            tap-ms = <U_ANTMORPH_MACRO_TAP>;
            // [p]PROJECT_
            bindings = <&macro_tap &kp BSPC &kp LS(P) &kp LS(R) &kp LS(O) &kp LS(J) &kp LS(E) &kp LS(C) &kp LS(T) &kp UNDER>;
        };
        amcmk_properties: amcmk_properties {
            compatible = "zmk,behavior-macro";
            #binding-cells = <0>;
            wait-ms = <U_ANTMORPH_MACRO_WAIT>;
            tap-ms = <U_ANTMORPH_MACRO_TAP>;
            // [p]PROPERTIES
            bindings = <&macro_tap &kp BSPC &kp LS(P) &kp LS(R) &kp LS(O) &kp LS(P) &kp LS(E) &kp LS(R) &kp LS(T) &kp LS(I) &kp LS(E) &kp LS(S)>;
        };
        // 'R'
        amcmk_required: amcmk_required {
            compatible = "zmk,behavior-macro";
            #binding-cells = <0>;
            wait-ms = <U_ANTMORPH_MACRO_WAIT>;
            tap-ms = <U_ANTMORPH_MACRO_TAP>;
            // [r]REQUIRED
            bindings = <&macro_tap &kp BSPC &kp LS(R) &kp LS(E) &kp LS(Q) &kp LS(U) &kp LS(I) &kp LS(R) &kp LS(E) &kp LS(D)>;
        };
        amcmk_return: amcmk_return {
            compatible = "zmk,behavior-macro";
            #binding-cells = <0>;
            wait-ms = <U_ANTMORPH_MACRO_WAIT>;
            tap-ms = <U_ANTMORPH_MACRO_TAP>;
            // (r)eturn(
            bindings = <&macro_tap &kp E &kp T &kp U &kp R &kp N &kp LPAR>;
        };
        amcmk_resourcegroups: amcmk_resourcegroups {
            compatible = "zmk,behavior-macro";
            #binding-cells = <0>;
            wait-ms = <U_ANTMORPH_MACRO_WAIT>;
            tap-ms = <U_ANTMORPH_MACRO_TAP>;
            // [r]RESOURCE_GROUPS
            bindings = <&macro_tap &kp BSPC &kp LS(R) &kp LS(E) &kp LS(S) &kp LS(O) &kp LS(U) &kp LS(R) &kp LS(C) &kp LS(E) &kp UNDER &kp LS(G) &kp LS(R) &kp LS(O) &kp LS(U) &kp LS(P) &kp LS(S)>;
        };
        amcmk_resourcelock: amcmk_resourcelock {
            compatible = "zmk,behavior-macro";
            #binding-cells = <0>;
            wait-ms = <U_ANTMORPH_MACRO_WAIT>;
            tap-ms = <U_ANTMORPH_MACRO_TAP>;
            // [r]RESOURCE_LOCK
            bindings = <&macro_release &kp RCTRL>, <&macro_tap &kp BSPC &kp LS(R) &kp LS(E) &kp LS(S) &kp LS(O) &kp LS(U) &kp LS(R) &kp LS(C) &kp LS(E) &kp UNDER &kp LS(L) &kp LS(O) &kp LS(C) &kp LS(K)>;
        };
        // 'S'
        amcmk_static: amcmk_static {
            compatible = "zmk,behavior-macro";
            #binding-cells = <0>;
            wait-ms = <U_ANTMORPH_MACRO_WAIT>;
            tap-ms = <U_ANTMORPH_MACRO_TAP>;
            // [s]STATIC
            bindings = <&macro_tap &kp BSPC &kp LS(S) &kp LS(T) &kp LS(A) &kp LS(T) &kp LS(I) &kp LS(C)>;
        };
        amcmk_shared: amcmk_shared {
            compatible = "zmk,behavior-macro";
            #binding-cells = <0>;
            wait-ms = <U_ANTMORPH_MACRO_WAIT>;
            tap-ms = <U_ANTMORPH_MACRO_TAP>;
            // [s]SHARED
            bindings = <&macro_release &kp LCTRL>, <&macro_tap &kp BSPC &kp LS(S) &kp LS(H) &kp LS(A) &kp LS(R) &kp LS(E) &kp LS(D)>;
        };
        amcmk_set: amcmk_set {
            compatible = "zmk,behavior-macro";
            #binding-cells = <0>;
            wait-ms = <U_ANTMORPH_MACRO_WAIT>;
            tap-ms = <U_ANTMORPH_MACRO_TAP>;
            // (s)et(
            bindings = <&macro_tap &kp E &kp T &kp LPAR>;
        };
        amcmk_setproperty: amcmk_setproperty {
            compatible = "zmk,behavior-macro";
            #binding-cells = <0>;
            wait-ms = <U_ANTMORPH_MACRO_WAIT>;
            tap-ms = <U_ANTMORPH_MACRO_TAP>;
            // (s)et_property(
            bindings = <&macro_tap &kp E &kp T &kp UNDER &kp P &kp R &kp O &kp P &kp E &kp R &kp T &kp Y &kp LPAR>;
        };
        amcmk_settestspropert: amcmk_settestspropert {
            compatible = "zmk,behavior-macro";
            #binding-cells = <0>;
            wait-ms = <U_ANTMORPH_MACRO_WAIT>;
            tap-ms = <U_ANTMORPH_MACRO_TAP>;
            // (s)et_tests_properties(
            bindings = <&macro_release &kp LCTRL>, <&macro_tap &kp E &kp T &kp UNDER &kp T &kp E &kp S &kp T &kp S &kp UNDER &kp P &kp R &kp O &kp P &kp E &kp R &kp T &kp I &kp E &kp S &kp LPAR>;
        };
        amcmk_string: amcmk_string {
            compatible = "zmk,behavior-macro";
            #binding-cells = <0>;
            wait-ms = <U_ANTMORPH_MACRO_WAIT>;
            tap-ms = <U_ANTMORPH_MACRO_TAP>;
            // (s)tring(
            bindings = <&macro_tap &kp T &kp R &kp I &kp N &kp G &kp LPAR>;
        };
        amcmk_settargetproper: amcmk_settargetproper {
            compatible = "zmk,behavior-macro";
            #binding-cells = <0>;
            wait-ms = <U_ANTMORPH_MACRO_WAIT>;
            tap-ms = <U_ANTMORPH_MACRO_TAP>;
            // (s)et_target_properties(
            bindings = <&macro_tap &kp E &kp T &kp UNDER &kp T &kp A &kp R &kp G &kp E &kp T &kp UNDER &kp P &kp R &kp O &kp P &kp E &kp R &kp T &kp I &kp E &kp S &kp LPAR>;
        };
        amcmk_setdirectorypro: amcmk_setdirectorypro {
            compatible = "zmk,behavior-macro";
            #binding-cells = <0>;
            wait-ms = <U_ANTMORPH_MACRO_WAIT>;
            tap-ms = <U_ANTMORPH_MACRO_TAP>;
            // (s)et_directory_properties(
            bindings = <&macro_release &kp RCTRL>, <&macro_tap &kp E &kp T &kp UNDER &kp D &kp I &kp R &kp E &kp C &kp T &kp O &kp R &kp Y &kp UNDER &kp P &kp R &kp O &kp P &kp E &kp R &kp T &kp I &kp E &kp S &kp LPAR>;
        };
        amcmk_setsourcefilesp: amcmk_setsourcefilesp {
            compatible = "zmk,behavior-macro";
            #binding-cells = <0>;
            wait-ms = <U_ANTMORPH_MACRO_WAIT>;
            tap-ms = <U_ANTMORPH_MACRO_TAP>;
            // (s)et_source_files_properties(
            bindings = <&macro_release &kp RCTRL>, <&macro_tap &kp E &kp T &kp UNDER &kp S &kp O &kp U &kp R &kp C &kp E &kp UNDER &kp F &kp I &kp L &kp E &kp S &kp UNDER &kp P &kp R &kp O &kp P &kp E &kp R &kp T &kp I &kp E &kp S &kp LPAR>;
        };
        // 'T'
        amcmk_targetsources: amcmk_targetsources {
            compatible = "zmk,behavior-macro";
            #binding-cells = <0>;
            wait-ms = <U_ANTMORPH_MACRO_WAIT>;
            tap-ms = <U_ANTMORPH_MACRO_TAP>;
            // (t)arget_sources(
            bindings = <&macro_tap &kp A &kp R &kp G &kp E &kp T &kp UNDER &kp S &kp O &kp U &kp R &kp C &kp E &kp S &kp LPAR>;
        };
        amcmk_targetlinklibra: amcmk_targetlinklibra {
            compatible = "zmk,behavior-macro";
            #binding-cells = <0>;
            wait-ms = <U_ANTMORPH_MACRO_WAIT>;
            tap-ms = <U_ANTMORPH_MACRO_TAP>;
            // (t)arget_link_libraries(
            bindings = <&macro_tap &kp A &kp R &kp G &kp E &kp T &kp UNDER &kp L &kp I &kp N &kp K &kp UNDER &kp L &kp I &kp B &kp R &kp A &kp R &kp I &kp E &kp S &kp LPAR>;
        };
        amcmk_targetlinkoptio: amcmk_targetlinkoptio {
            compatible = "zmk,behavior-macro";
            #binding-cells = <0>;
            wait-ms = <U_ANTMORPH_MACRO_WAIT>;
            tap-ms = <U_ANTMORPH_MACRO_TAP>;
            // (t)arget_link_options(
            bindings = <&macro_release &kp LCTRL>, <&macro_tap &kp A &kp R &kp G &kp E &kp T &kp UNDER &kp L &kp I &kp N &kp K &kp UNDER &kp O &kp P &kp T &kp I &kp O &kp N &kp S &kp LPAR>;
        };
        amcmk_targetlinkdirec: amcmk_targetlinkdirec {
            compatible = "zmk,behavior-macro";
            #binding-cells = <0>;
            wait-ms = <U_ANTMORPH_MACRO_WAIT>;
            tap-ms = <U_ANTMORPH_MACRO_TAP>;
            // (t)arget_link_directories(
            bindings = <&macro_tap &kp A &kp R &kp G &kp E &kp T &kp UNDER &kp L &kp I &kp N &kp K &kp UNDER &kp D &kp I &kp R &kp E &kp C &kp T &kp O &kp R &kp I &kp E &kp S &kp LPAR>;
        };
        amcmk_targetincludedi: amcmk_targetincludedi {
            compatible = "zmk,behavior-macro";
            #binding-cells = <0>;
            wait-ms = <U_ANTMORPH_MACRO_WAIT>;
            tap-ms = <U_ANTMORPH_MACRO_TAP>;
            // (t)arget_include_directories(
            bindings = <&macro_tap &kp A &kp R &kp G &kp E &kp T &kp UNDER &kp I &kp N &kp C &kp L &kp U &kp D &kp E &kp UNDER &kp D &kp I &kp R &kp E &kp C &kp T &kp O &kp R &kp I &kp E &kp S &kp LPAR>;
        };
        amcmk_targetprecompil: amcmk_targetprecompil {
            compatible = "zmk,behavior-macro";
            #binding-cells = <0>;
            wait-ms = <U_ANTMORPH_MACRO_WAIT>;
            tap-ms = <U_ANTMORPH_MACRO_TAP>;
            // (t)arget_precompile_headers(
            bindings = <&macro_release &kp RCTRL>, <&macro_tap &kp A &kp R &kp G &kp E &kp T &kp UNDER &kp P &kp R &kp E &kp C &kp O &kp M &kp P &kp I &kp L &kp E &kp UNDER &kp H &kp E &kp A &kp D &kp E &kp R &kp S &kp LPAR>;
        };
        amcmk_targetcompilede: amcmk_targetcompilede {
            compatible = "zmk,behavior-macro";
            #binding-cells = <0>;
            wait-ms = <U_ANTMORPH_MACRO_WAIT>;
            tap-ms = <U_ANTMORPH_MACRO_TAP>;
            // (t)arget_compile_definitions(
            bindings = <&macro_tap &kp A &kp R &kp G &kp E &kp T &kp UNDER &kp C &kp O &kp M &kp P &kp I &kp L &kp E &kp UNDER &kp D &kp E &kp F &kp I &kp N &kp I &kp T &kp I &kp O &kp N &kp S &kp LPAR>;
        };
        amcmk_targetcompileop: amcmk_targetcompileop {
            compatible = "zmk,behavior-macro";
            #binding-cells = <0>;
            wait-ms = <U_ANTMORPH_MACRO_WAIT>;
            tap-ms = <U_ANTMORPH_MACRO_TAP>;
            // (t)arget_compile_options(
            bindings = <&macro_release &kp RCTRL>, <&macro_tap &kp A &kp R &kp G &kp E &kp T &kp UNDER &kp C &kp O &kp M &kp P &kp I &kp L &kp E &kp UNDER &kp O &kp P &kp T &kp I &kp O &kp N &kp S &kp LPAR>;
        };
        amcmk_targetcompilefe: amcmk_targetcompilefe {
            compatible = "zmk,behavior-macro";
            #binding-cells = <0>;
            wait-ms = <U_ANTMORPH_MACRO_WAIT>;
            tap-ms = <U_ANTMORPH_MACRO_TAP>;
            // (t)arget_compile_features(
            bindings = <&macro_release &kp RALT>, <&macro_tap &kp RALT>, <&macro_tap &kp A &kp R &kp G &kp E &kp T &kp UNDER &kp C &kp O &kp M &kp P &kp I &kp L &kp E &kp UNDER &kp F &kp E &kp A &kp T &kp U &kp R &kp E &kp S &kp LPAR>;
        };
        // 'V'
        amcmk_version: amcmk_version {
            compatible = "zmk,behavior-macro";
            #binding-cells = <0>;
            wait-ms = <U_ANTMORPH_MACRO_WAIT>;
            tap-ms = <U_ANTMORPH_MACRO_TAP>;
            // [v]VERSION
            bindings = <&macro_tap &kp BSPC &kp LS(V) &kp LS(E) &kp LS(R) &kp LS(S) &kp LS(I) &kp LS(O) &kp LS(N)>;
        };
        // 'W'
        amcmk_while: amcmk_while {
            compatible = "zmk,behavior-macro";
            #binding-cells = <0>;
            wait-ms = <U_ANTMORPH_MACRO_WAIT>;
            tap-ms = <U_ANTMORPH_MACRO_TAP>;
            // (w)hile(
            bindings = <&macro_tap &kp H &kp I &kp L &kp E &kp LPAR>;
        };
        amcmk_endwhile: amcmk_endwhile {
            compatible = "zmk,behavior-macro";
            #binding-cells = <0>;
            wait-ms = <U_ANTMORPH_MACRO_WAIT>;
            tap-ms = <U_ANTMORPH_MACRO_TAP>;
            // [w]endwhile()
            bindings = <&macro_release &kp LCTRL>, <&macro_tap &kp BSPC &kp E &kp N &kp D &kp W &kp H &kp I &kp L &kp E &kp LPAR &kp RPAR>;
        };
        // 'Y'
        amcmk_true: amcmk_true {
            compatible = "zmk,behavior-macro";
            #binding-cells = <0>;
            wait-ms = <U_ANTMORPH_MACRO_WAIT>;
            tap-ms = <U_ANTMORPH_MACRO_TAP>;
            // [y]TRUE
            bindings = <&macro_tap &kp BSPC &kp LS(T) &kp LS(R) &kp LS(U) &kp LS(E)>;
        };
        // '0'
        amcmk_01: amcmk_01 {
            compatible = "zmk,behavior-macro";
            #binding-cells = <0>;
            wait-ms = <U_ANTMORPH_MACRO_WAIT>;
            tap-ms = <U_ANTMORPH_MACRO_TAP>;
            // (0).1
            bindings = <&macro_tap &kp DOT &kp N1>;
        };
        // '1'
        amcmk_10: amcmk_10 {
            compatible = "zmk,behavior-macro";
            #binding-cells = <0>;
            wait-ms = <U_ANTMORPH_MACRO_WAIT>;
            tap-ms = <U_ANTMORPH_MACRO_TAP>;
            // (1).0
            bindings = <&macro_tap &kp DOT &kp N0>;
        };
        // '3'
        amcmk_330: amcmk_330 {
            compatible = "zmk,behavior-macro";
            #binding-cells = <0>;
            wait-ms = <U_ANTMORPH_MACRO_WAIT>;
            tap-ms = <U_ANTMORPH_MACRO_TAP>;
            // (3).30
            bindings = <&macro_tap &kp DOT &kp N3 &kp N0>;
        };
        // '.'
        amcmk_cmake1: amcmk_cmake1 {
            compatible = "zmk,behavior-macro";
            #binding-cells = <0>;
            wait-ms = <U_ANTMORPH_MACRO_WAIT>;
            tap-ms = <U_ANTMORPH_MACRO_TAP>;
            // (.)cmake
            bindings = <&macro_tap &kp C &kp M &kp A &kp K &kp E>;
        };
        // '''
        amcmk_m: amcmk_m {
            compatible = "zmk,behavior-macro";
            #binding-cells = <0>;
            wait-ms = <U_ANTMORPH_MACRO_WAIT>;
            tap-ms = <U_ANTMORPH_MACRO_TAP>;
            // (')]]
            bindings = <&macro_tap &kp RBKT &kp RBKT>;
        };
        // '/'
        amcmk_bool1: amcmk_bool1 {
            compatible = "zmk,behavior-macro";
            #binding-cells = <0>;
            wait-ms = <U_ANTMORPH_MACRO_WAIT>;
            tap-ms = <U_ANTMORPH_MACRO_TAP>;
            // [/]$<$<BOOL:
            bindings = <&macro_tap &kp BSPC &kp DLLR &kp LT &kp DLLR &kp LT &kp LS(B) &kp LS(O) &kp LS(O) &kp LS(L) &kp COLON>;
        };
        amcmk_if1: amcmk_if1 {
            compatible = "zmk,behavior-macro";
            #binding-cells = <0>;
            wait-ms = <U_ANTMORPH_MACRO_WAIT>;
            tap-ms = <U_ANTMORPH_MACRO_TAP>;
            // [/]$<IF:
            bindings = <&macro_tap &kp BSPC &kp DLLR &kp LT &kp LS(I) &kp LS(F) &kp COLON>;
        };
        // '$'
        amcmk_m1: amcmk_m1 {
            compatible = "zmk,behavior-macro";
            #binding-cells = <0>;
            wait-ms = <U_ANTMORPH_MACRO_WAIT>;
            tap-ms = <U_ANTMORPH_MACRO_TAP>;
            // ($)<$<
            bindings = <&macro_release &kp LCTRL>, <&macro_tap &kp LT &kp DLLR &kp LT>;
        };
        amcmk_cmake2: amcmk_cmake2 {
            compatible = "zmk,behavior-macro";
            #binding-cells = <0>;
            wait-ms = <U_ANTMORPH_MACRO_WAIT>;
            tap-ms = <U_ANTMORPH_MACRO_TAP>;
            // ($){CMAKE_
            bindings = <&macro_release &kp LCTRL>, <&macro_tap &kp LBRC &kp LS(C) &kp LS(M) &kp LS(A) &kp LS(K) &kp LS(E) &kp UNDER>;
        };
        amcmk_cmakecommand: amcmk_cmakecommand {
            compatible = "zmk,behavior-macro";
            #binding-cells = <0>;
            wait-ms = <U_ANTMORPH_MACRO_WAIT>;
            tap-ms = <U_ANTMORPH_MACRO_TAP>;
            // ($){CMAKE_COMMAND}
            bindings = <&macro_tap &kp LBRC &kp LS(C) &kp LS(M) &kp LS(A) &kp LS(K) &kp LS(E) &kp UNDER &kp LS(C) &kp LS(O) &kp LS(M) &kp LS(M) &kp LS(A) &kp LS(N) &kp LS(D) &kp RBRC>;
        };
        // '!'
        amcmk_not: amcmk_not {
            compatible = "zmk,behavior-macro";
            #binding-cells = <0>;
            wait-ms = <U_ANTMORPH_MACRO_WAIT>;
            tap-ms = <U_ANTMORPH_MACRO_TAP>;
            // [!]$<NOT:
            bindings = <&macro_tap &kp BSPC &kp DLLR &kp LT &kp LS(N) &kp LS(O) &kp LS(T) &kp COLON>;
        };
        // '@'
        amcmk_only: amcmk_only {
            compatible = "zmk,behavior-macro";
            #binding-cells = <0>;
            wait-ms = <U_ANTMORPH_MACRO_WAIT>;
            tap-ms = <U_ANTMORPH_MACRO_TAP>;
            // (@)ONLY
            bindings = <&macro_tap &kp LS(O) &kp LS(N) &kp LS(L) &kp LS(Y)>;
        };
        // '|'
        amcmk_or: amcmk_or {
            compatible = "zmk,behavior-macro";
            #binding-cells = <0>;
            wait-ms = <U_ANTMORPH_MACRO_WAIT>;
            tap-ms = <U_ANTMORPH_MACRO_TAP>;
            // [|]$<OR:
            bindings = <&macro_tap &kp BSPC &kp DLLR &kp LT &kp LS(O) &kp LS(R) &kp COLON>;
        };
        // '&'
        amcmk_and: amcmk_and {
            compatible = "zmk,behavior-macro";
            #binding-cells = <0>;
            wait-ms = <U_ANTMORPH_MACRO_WAIT>;
            tap-ms = <U_ANTMORPH_MACRO_TAP>;
            // [&]$<AND:
            bindings = <&macro_tap &kp BSPC &kp DLLR &kp LT &kp LS(A) &kp LS(N) &kp LS(D) &kp COLON>;
        };
        // '_'
        amcmk_standard: amcmk_standard {
            compatible = "zmk,behavior-macro";
            #binding-cells = <0>;
            wait-ms = <U_ANTMORPH_MACRO_WAIT>;
            tap-ms = <U_ANTMORPH_MACRO_TAP>;
            // (_)STANDARD
            bindings = <&macro_tap &kp LS(S) &kp LS(T) &kp LS(A) &kp LS(N) &kp LS(D) &kp LS(A) &kp LS(R) &kp LS(D)>;
        };
        amcmk_standardrequire: amcmk_standardrequire {
            compatible = "zmk,behavior-macro";
            #binding-cells = <0>;
            wait-ms = <U_ANTMORPH_MACRO_WAIT>;
            tap-ms = <U_ANTMORPH_MACRO_TAP>;
            // (_)STANDARD_REQUIRED
            bindings = <&macro_release &kp LCTRL>, <&macro_tap &kp LS(S) &kp LS(T) &kp LS(A) &kp LS(N) &kp LS(D) &kp LS(A) &kp LS(R) &kp LS(D) &kp UNDER &kp LS(R) &kp LS(E) &kp LS(Q) &kp LS(U) &kp LS(I) &kp LS(R) &kp LS(E) &kp LS(D)>;
        };
        amcmk_standardextensi: amcmk_standardextensi {
            compatible = "zmk,behavior-macro";
            #binding-cells = <0>;
            wait-ms = <U_ANTMORPH_MACRO_WAIT>;
            tap-ms = <U_ANTMORPH_MACRO_TAP>;
            // (_)STANDARD_EXTENSIONS
            bindings = <&macro_release &kp LALT>, <&macro_tap &kp LALT>, <&macro_tap &kp LS(S) &kp LS(T) &kp LS(A) &kp LS(N) &kp LS(D) &kp LS(A) &kp LS(R) &kp LS(D) &kp UNDER &kp LS(E) &kp LS(X) &kp LS(T) &kp LS(E) &kp LS(N) &kp LS(S) &kp LS(I) &kp LS(O) &kp LS(N) &kp LS(S)>;
        };
        amcmk_currentsourcedi: amcmk_currentsourcedi {
            compatible = "zmk,behavior-macro";
            #binding-cells = <0>;
            wait-ms = <U_ANTMORPH_MACRO_WAIT>;
            tap-ms = <U_ANTMORPH_MACRO_TAP>;
            // (_)CURRENT_SOURCE_DIR
            bindings = <&macro_tap &kp LS(C) &kp LS(U) &kp LS(R) &kp LS(R) &kp LS(E) &kp LS(N) &kp LS(T) &kp UNDER &kp LS(S) &kp LS(O) &kp LS(U) &kp LS(R) &kp LS(C) &kp LS(E) &kp UNDER &kp LS(D) &kp LS(I) &kp LS(R)>;
        };
        amcmk_currentbinarydi: amcmk_currentbinarydi {
            compatible = "zmk,behavior-macro";
            #binding-cells = <0>;
            wait-ms = <U_ANTMORPH_MACRO_WAIT>;
            tap-ms = <U_ANTMORPH_MACRO_TAP>;
            // (_)CURRENT_BINARY_DIR
            bindings = <&macro_release &kp LCTRL>, <&macro_tap &kp LS(C) &kp LS(U) &kp LS(R) &kp LS(R) &kp LS(E) &kp LS(N) &kp LS(T) &kp UNDER &kp LS(B) &kp LS(I) &kp LS(N) &kp LS(A) &kp LS(R) &kp LS(Y) &kp UNDER &kp LS(D) &kp LS(I) &kp LS(R)>;
        };
        amcmk_currentlistdir: amcmk_currentlistdir {
            compatible = "zmk,behavior-macro";
            #binding-cells = <0>;
            wait-ms = <U_ANTMORPH_MACRO_WAIT>;
            tap-ms = <U_ANTMORPH_MACRO_TAP>;
            // (_)CURRENT_LIST_DIR
            bindings = <&macro_release &kp LALT>, <&macro_tap &kp LALT>, <&macro_tap &kp LS(C) &kp LS(U) &kp LS(R) &kp LS(R) &kp LS(E) &kp LS(N) &kp LS(T) &kp UNDER &kp LS(L) &kp LS(I) &kp LS(S) &kp LS(T) &kp UNDER &kp LS(D) &kp LS(I) &kp LS(R)>;
        };
        amcmk_currentlistfile: amcmk_currentlistfile {
            compatible = "zmk,behavior-macro";
            #binding-cells = <0>;
            wait-ms = <U_ANTMORPH_MACRO_WAIT>;
            tap-ms = <U_ANTMORPH_MACRO_TAP>;
            // (_)CURRENT_LIST_FILE
            bindings = <&macro_release &kp LGUI>, <&macro_tap &kp LGUI>, <&macro_tap &kp LS(C) &kp LS(U) &kp LS(R) &kp LS(R) &kp LS(E) &kp LS(N) &kp LS(T) &kp UNDER &kp LS(L) &kp LS(I) &kp LS(S) &kp LS(T) &kp UNDER &kp LS(F) &kp LS(I) &kp LS(L) &kp LS(E)>;
        };
        amcmk_regularexpressi: amcmk_regularexpressi {
            compatible = "zmk,behavior-macro";
            #binding-cells = <0>;
            wait-ms = <U_ANTMORPH_MACRO_WAIT>;
            tap-ms = <U_ANTMORPH_MACRO_TAP>;
            // (_)REGULAR_EXPRESSION
            bindings = <&macro_tap &kp LS(R) &kp LS(E) &kp LS(G) &kp LS(U) &kp LS(L) &kp LS(A) &kp LS(R) &kp UNDER &kp LS(E) &kp LS(X) &kp LS(P) &kp LS(R) &kp LS(E) &kp LS(S) &kp LS(S) &kp LS(I) &kp LS(O) &kp LS(N)>;
        };
        amcmk_istoplevel: amcmk_istoplevel {
            compatible = "zmk,behavior-macro";
            #binding-cells = <0>;
            wait-ms = <U_ANTMORPH_MACRO_WAIT>;
            tap-ms = <U_ANTMORPH_MACRO_TAP>;
            // (_)IS_TOP_LEVEL
            bindings = <&macro_release &kp LCTRL>, <&macro_tap &kp LS(I) &kp LS(S) &kp UNDER &kp LS(T) &kp LS(O) &kp LS(P) &kp UNDER &kp LS(L) &kp LS(E) &kp LS(V) &kp LS(E) &kp LS(L)>;
        };
        amcmk_install1: amcmk_install1 {
            compatible = "zmk,behavior-macro";
            #binding-cells = <0>;
            wait-ms = <U_ANTMORPH_MACRO_WAIT>;
            tap-ms = <U_ANTMORPH_MACRO_TAP>;
            // (_)INSTALL_
            bindings = <&macro_tap &kp LS(I) &kp LS(N) &kp LS(S) &kp LS(T) &kp LS(A) &kp LS(L) &kp LS(L) &kp UNDER>;
        };
        amcmk_std: amcmk_std {
            compatible = "zmk,behavior-macro";
            #binding-cells = <0>;
            wait-ms = <U_ANTMORPH_MACRO_WAIT>;
            tap-ms = <U_ANTMORPH_MACRO_TAP>;
            // (_)std_
            bindings = <&macro_tap &kp S &kp T &kp D &kp UNDER>;
        };
        // '['
        amcmk_m2: amcmk_m2 {
            compatible = "zmk,behavior-macro";
            #binding-cells = <0>;
            wait-ms = <U_ANTMORPH_MACRO_WAIT>;
            tap-ms = <U_ANTMORPH_MACRO_TAP>;
            // ([)["
            bindings = <&macro_tap &kp LBKT &kp DQT>;
        };
        amcmk_m3: amcmk_m3 {
            compatible = "zmk,behavior-macro";
            #binding-cells = <0>;
            wait-ms = <U_ANTMORPH_MACRO_WAIT>;
            tap-ms = <U_ANTMORPH_MACRO_TAP>;
            // ([)=[
            bindings = <&macro_tap &kp EQUAL &kp LBKT>;
        };
        amcmk_m4: amcmk_m4 {
            compatible = "zmk,behavior-macro";
            #binding-cells = <0>;
            wait-ms = <U_ANTMORPH_MACRO_WAIT>;
            tap-ms = <U_ANTMORPH_MACRO_TAP>;
            // ([)==[
            bindings = <&macro_release &kp LCTRL>, <&macro_tap &kp EQUAL &kp EQUAL &kp LBKT>;
        };
        amcmk_m5: amcmk_m5 {
            compatible = "zmk,behavior-macro";
            #binding-cells = <0>;
            wait-ms = <U_ANTMORPH_MACRO_WAIT>;
            tap-ms = <U_ANTMORPH_MACRO_TAP>;
            // ([)===[
            bindings = <&macro_release &kp LALT>, <&macro_tap &kp LALT>, <&macro_tap &kp EQUAL &kp EQUAL &kp EQUAL &kp LBKT>;
        };
        // ']'
        amcmk_m6: amcmk_m6 {
            compatible = "zmk,behavior-macro";
            #binding-cells = <0>;
            wait-ms = <U_ANTMORPH_MACRO_WAIT>;
            tap-ms = <U_ANTMORPH_MACRO_TAP>;
            // (])=]
            bindings = <&macro_tap &kp EQUAL &kp RBKT>;
        };
        amcmk_m7: amcmk_m7 {
            compatible = "zmk,behavior-macro";
            #binding-cells = <0>;
            wait-ms = <U_ANTMORPH_MACRO_WAIT>;
            tap-ms = <U_ANTMORPH_MACRO_TAP>;
            // (])==]
            bindings = <&macro_release &kp LCTRL>, <&macro_tap &kp EQUAL &kp EQUAL &kp RBKT>;
        };
        amcmk_m8: amcmk_m8 {
            compatible = "zmk,behavior-macro";
            #binding-cells = <0>;
            wait-ms = <U_ANTMORPH_MACRO_WAIT>;
            tap-ms = <U_ANTMORPH_MACRO_TAP>;
            // (])===]
            bindings = <&macro_release &kp LALT>, <&macro_tap &kp LALT>, <&macro_tap &kp EQUAL &kp EQUAL &kp EQUAL &kp RBKT>;
        };
        // ' '
        amcmk_cmake_v08: amcmk_cmake_v08 {
            compatible = "zmk,behavior-macro";
            #binding-cells = <0>;
            wait-ms = <U_ANTMORPH_MACRO_WAIT>;
            tap-ms = <U_ANTMORPH_MACRO_TAP>;
            // [ ]CMake v0.8
            bindings = <&macro_tap &kp BSPC &kp LS(C) &kp LS(M) &kp A &kp K &kp E &kp SPACE &kp V &kp N0 &kp DOT &kp N8>;
        };
    };
};
